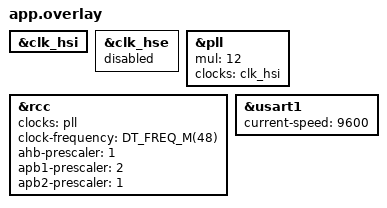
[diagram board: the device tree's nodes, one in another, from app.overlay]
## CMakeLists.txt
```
cmake_minimum_required(VERSION 3.20.0)

# Find the Zephyr OS
find_package(Zephyr REQUIRED HINTS $ENV{ZEPHYR_BASE})

# Create the project
project(microinverter)

# Add the C file
target_sources(app PRIVATE src/main.c)
```

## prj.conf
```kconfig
# --- Hardware ---
CONFIG_GPIO=y

# --- Logging & Console ---
CONFIG_LOG=y
CONFIG_LOG_MODE_MINIMAL=y
CONFIG_SHELL=y
CONFIG_SHELL_BACKEND_SERIAL=y

# --- Critical for Clones & Stability ---
# Increase stack size so Shell + Logging doesn't crash the Clone
CONFIG_MAIN_STACK_SIZE=4096
CONFIG_SYSTEM_WORKQUEUE_STACK_SIZE=2048

# --- Math Support ---
# Required for our voltage calculations (float)
CONFIG_CBPRINTF_FP_SUPPORT=y

# Disable ANSI Colors (Cleans up the [1;32m garbage)
CONFIG_SHELL_VT100_COLORS=n
CONFIG_LOG_BACKEND_SHOW_COLOR=n
```

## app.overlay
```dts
/* Clone-Safe Configuration for STM32F103 Blue Pill */
/* Forces usage of Internal 8MHz Oscillator (HSI) instead of External Crystal */

/* 1. Enable Internal 8MHz Oscillator */
&clk_hsi {
    status = "okay";
};

/* 2. Disable External Oscillator (The most common failure point on clones) */
&clk_hse {
    status = "disabled";
};

/* 3. Configure PLL (Phase Locked Loop) */
/* HSI (8MHz) is internally divided by 2 -> 4MHz entering PLL */
/* We multiply by 12 to get 48MHz System Clock (Safe & Fast) */
&pll {
    mul = <12>;
    clocks = <&clk_hsi>;
    status = "okay";
};

/* 4. Set the System Clock to use the PLL */
&rcc {
    clocks = <&pll>;
    clock-frequency = <DT_FREQ_M(48)>;
    ahb-prescaler = <1>;
    apb1-prescaler = <2>;
    apb2-prescaler = <1>;
};

/* ... (Keep your existing clock config above this) ... */

/* Change UART speed to 9600 for Arduino SoftwareSerial compatibility */
&usart1 {
    current-speed = <9600>;
    status = "okay";
};
```

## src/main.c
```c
#include <zephyr/kernel.h>
#include <zephyr/drivers/gpio.h>
#include <zephyr/logging/log.h>
#include <zephyr/shell/shell.h>
#include <stdlib.h>

// Register module for logging
LOG_MODULE_REGISTER(microinverter, LOG_LEVEL_INF);

// --- HARDWARE ---
// Blue Pill LED (PC13)
static const struct gpio_dt_spec led = GPIO_DT_SPEC_GET(DT_ALIAS(led0), gpios);

// --- MOCK STATE ---
static float simulated_voltage = 0.0f;
static bool auto_simulation_mode = true;

// --- THREAD 1: SOLAR PHYSICS SIMULATOR ---
// Runs every 100ms to update voltage
void solar_simulation_thread(void)
{
    bool rising = true;
    
    while (1) {
        if (auto_simulation_mode) {
            // Simulate Day (0V -> 50V) and Night (50V -> 0V)
            if (rising) {
                simulated_voltage += 0.5f;
                if (simulated_voltage >= 50.0f) rising = false;
            } else {
                simulated_voltage -= 0.5f;
                if (simulated_voltage <= 0.0f) rising = true;
            }
        }
        k_msleep(100);
    }
}

// --- THREAD 2: INVERTER CONTROL LOOP ---
// The "Job 1" Logic: Monitor Voltage -> Control Hardware
void control_thread(void)
{
    if (!gpio_is_ready_dt(&led)) return;
    gpio_pin_configure_dt(&led, GPIO_OUTPUT_ACTIVE);

    while (1) {
        // Logic: Inverter only works between 20V and 45V
        bool grid_ok = (simulated_voltage > 20.0f && simulated_voltage < 45.0f);

        if (grid_ok) {
            // Normal Operation: LED Solid ON (Active Low = 1)
            gpio_pin_set_dt(&led, 1); 
            // LOG_INF("Status: GENERATING | Voltage: %d V", (int)simulated_voltage);
        } else {
            // Fault Mode: Blink LED
            gpio_pin_toggle_dt(&led);
            // LOG_WRN("Status: FAULT      | Voltage: %d V", (int)simulated_voltage);
        }

        k_msleep(200); // Check 5 times per second
    }
}

// --- DEFINE THREADS ---
// Create threads with generous stack sizes for safety
K_THREAD_DEFINE(sim_tid, 1024, solar_simulation_thread, NULL, NULL, NULL, 7, 0, 0);
K_THREAD_DEFINE(ctrl_tid, 1024, control_thread, NULL, NULL, NULL, 5, 0, 0);

// --- SHELL COMMANDS ---
// Commands to type in terminal: "sensor set <val>" or "sensor auto"
static int cmd_set_voltage(const struct shell *shell, size_t argc, char **argv)
{
    if (argc < 2) {
        shell_print(shell, "Usage: sensor set <voltage>");
        return -1;
    }
    auto_simulation_mode = false;
    simulated_voltage = (float)atoi(argv[1]);
    shell_print(shell, "Manual Override: %d V", (int)simulated_voltage);
    return 0;
}

static int cmd_auto_mode(const struct shell *shell, size_t argc, char **argv)
{
    auto_simulation_mode = true;
    shell_print(shell, "Auto Simulation Enabled");
    return 0;
}

SHELL_STATIC_SUBCMD_SET_CREATE(sub_sensor,
    SHELL_CMD(set, NULL, "Set voltage manually", cmd_set_voltage),
    SHELL_CMD(auto, NULL, "Enable auto simulation", cmd_auto_mode),
    SHELL_SUBCMD_SET_END
);
SHELL_CMD_REGISTER(sensor, &sub_sensor, "Sensor Simulation Commands", NULL);
```
